# STM32H723VEH6 register map
File version: 1.0
Registers are 32-bit, access not given, reset 0x0 unless marked. A register's access mark holds for its fields unless they carry their own. Offsets are from the block's base; [hi:lo] are bit positions; {n}, {i} and the like mark numbered series.

## DMA1
Base 0x40020000
Same registers: DMA2 0x40020400
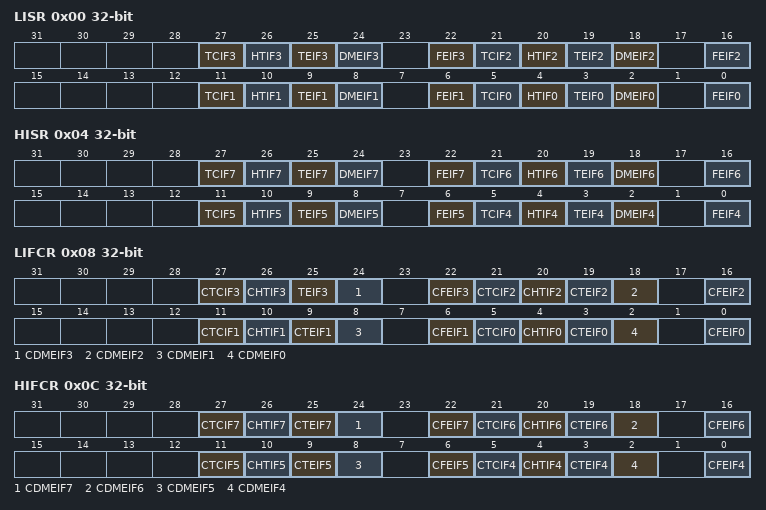
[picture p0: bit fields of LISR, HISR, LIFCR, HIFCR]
0x00 LISR
  [27] TCIF3, [26] HTIF3, [25] TEIF3, [24] DMEIF3, [22] FEIF3, [21] TCIF2, [20] HTIF2, [19] TEIF2, [18] DMEIF2, [16] FEIF2, [11] TCIF1, [10] HTIF1, [9] TEIF1, [8] DMEIF1, [6] FEIF1, [5] TCIF0, [4] HTIF0, [3] TEIF0, [2] DMEIF0, [0] FEIF0
0x04 HISR
  [27] TCIF7, [26] HTIF7, [25] TEIF7, [24] DMEIF7, [22] FEIF7, [21] TCIF6, [20] HTIF6, [19] TEIF6, [18] DMEIF6, [16] FEIF6, [11] TCIF5, [10] HTIF5, [9] TEIF5, [8] DMEIF5, [6] FEIF5, [5] TCIF4, [4] HTIF4, [3] TEIF4, [2] DMEIF4, [0] FEIF4
0x08 LIFCR
  [27] CTCIF3, [26] CHTIF3, [25] TEIF3, [24] CDMEIF3, [22] CFEIF3, [21] CTCIF2, [20] CHTIF2, [19] CTEIF2, [18] CDMEIF2, [16] CFEIF2, [11] CTCIF1, [10] CHTIF1, [9] CTEIF1, [8] CDMEIF1, [6] CFEIF1, [5] CTCIF0, [4] CHTIF0, [3] CTEIF0, [2] CDMEIF0, [0] CFEIF0
0x0C HIFCR
  [27] CTCIF7, [26] CHTIF7, [25] CTEIF7, [24] CDMEIF7, [22] CFEIF7, [21] CTCIF6, [20] CHTIF6, [19] CTEIF6, [18] CDMEIF6, [16] CFEIF6, [11] CTCIF5, [10] CHTIF5, [9] CTEIF5, [8] CDMEIF5, [6] CFEIF5, [5] CTCIF4, [4] CHTIF4, [3] CTEIF4, [2] CDMEIF4, [0] CFEIF4
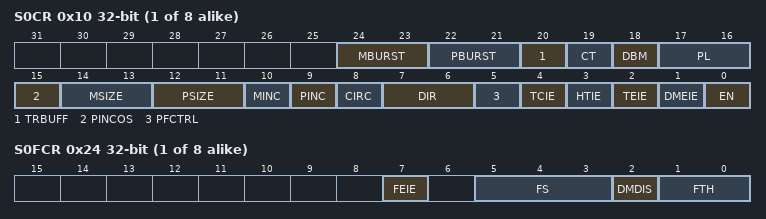
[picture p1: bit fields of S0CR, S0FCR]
{0x10+0x18*i} S{i}CR (i=0..7)
  [24:23] MBURST, [22:21] PBURST, [20] TRBUFF, [19] CT, [18] DBM, [17:16] PL, [15] PINCOS, [14:13] MSIZE, [12:11] PSIZE, [10] MINC, [9] PINC, [8] CIRC, [7:6] DIR, [5] PFCTRL, [4] TCIE, [3] HTIE, [2] TEIE, [1] DMEIE, [0] EN
{0x14+0x18*i} S{i}NDTR (i=0..7)
  [15:0] NDT
{0x18+0x18*i} S{i}PAR (i=0..7)
  [31:0] PA
{0x1C+0x18*i} S{i}M0AR (i=0..7)
  [31:0] M0A
{0x20+0x18*i} S{i}M1AR (i=0..7)
  [31:0] M1A
{0x24+0x18*i} S{i}FCR (i=0..7)
  [7] FEIE, [5:3] FS, [2] DMDIS, [1:0] FTH

## DMAMUX1
Base 0x40020800
Same registers: DMAMUX2 0x58025800
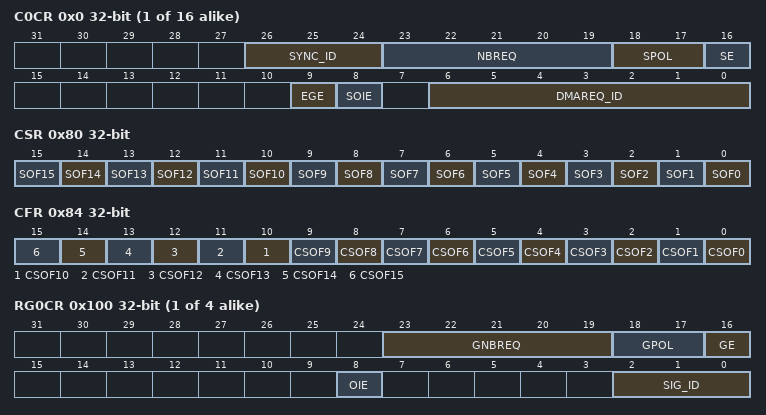
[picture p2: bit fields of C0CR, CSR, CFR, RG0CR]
{0x0+4i} C{i}CR (i=0..15)
  [26:24] SYNC_ID, [23:19] NBREQ, [18:17] SPOL, [16] SE, [9] EGE, [8] SOIE, [6:0] DMAREQ_ID
0x80 CSR
  [n] SOF{n} (n=0..15)
0x84 CFR
  [n] CSOF{n} (n=0..15)
{0x100+4i} RG{i}CR (i=0..3)
  [23:19] GNBREQ, [18:17] GPOL, [16] GE, [8] OIE, [2:0] SIG_ID
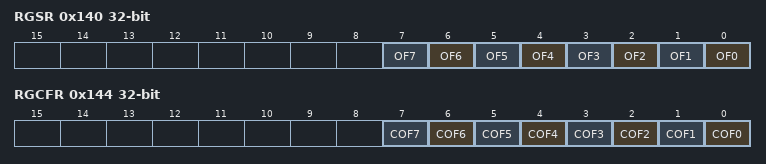
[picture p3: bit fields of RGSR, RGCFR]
0x140 RGSR
  [n] OF{n} (n=0..7)
0x144 RGCFR
  [n] COF{n} (n=0..7)

## ADC1
Base 0x40022000
Same registers: ADC2 0x40022000, ADC3 0x58026000
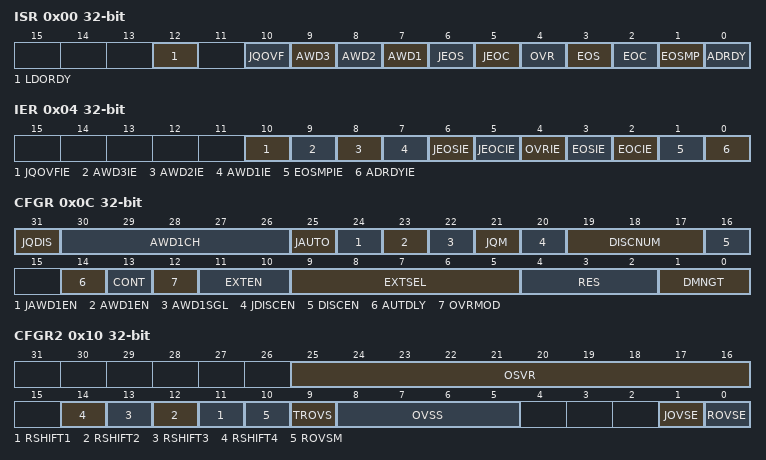
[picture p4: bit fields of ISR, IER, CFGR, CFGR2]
0x00 ISR
  [12] LDORDY, [10] JQOVF, [9] AWD3, [8] AWD2, [7] AWD1, [6] JEOS, [5] JEOC, [4] OVR, [3] EOS, [2] EOC, [1] EOSMP, [0] ADRDY
0x04 IER
  [10] JQOVFIE, [9] AWD3IE, [8] AWD2IE, [7] AWD1IE, [6] JEOSIE, [5] JEOCIE, [4] OVRIE, [3] EOSIE, [2] EOCIE, [1] EOSMPIE, [0] ADRDYIE
0x0C CFGR
  [31] JQDIS, [30:26] AWD1CH, [25] JAUTO, [24] JAWD1EN, [23] AWD1EN, [22] AWD1SGL, [21] JQM, [20] JDISCEN, [19:17] DISCNUM, [16] DISCEN, [14] AUTDLY, [13] CONT, [12] OVRMOD, [11:10] EXTEN, [9:5] EXTSEL, [4:2] RES, [1:0] DMNGT
0x10 CFGR2
  [25:16] OSVR, [n+10] RSHIFT{n} (n=1..4), [10] ROVSM, [9] TROVS, [8:5] OVSS, [1] JOVSE, [0] ROVSE
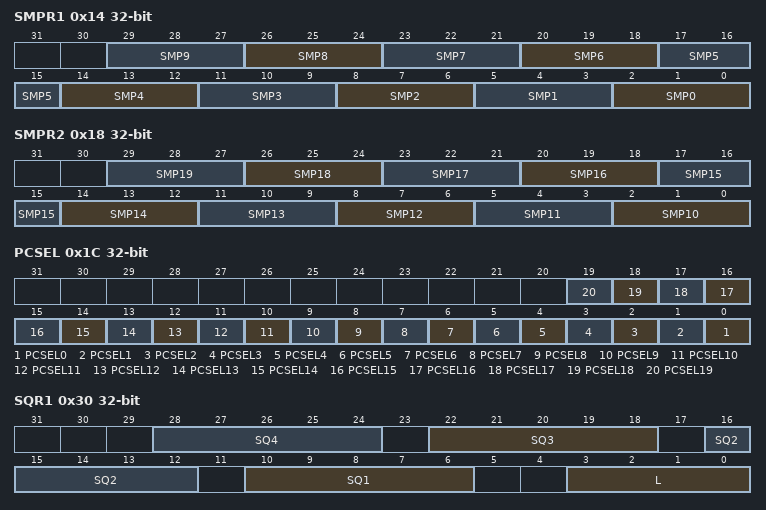
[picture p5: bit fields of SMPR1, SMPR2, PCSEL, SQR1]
0x14 SMPR1
  [3n+2:3n] SMP{n} (n=0..9)
0x18 SMPR2
  [3n-28:3n-30] SMP{n} (n=10..19)
0x1C PCSEL
  [n] PCSEL{n} (n=0..19)
0x20 LTR1
  [25:0] LTR1
0x24 HTR1
  [25:0] HTR1
0x30 SQR1
  [6n+4:6n] SQ{n} (n=1..4), [3:0] L
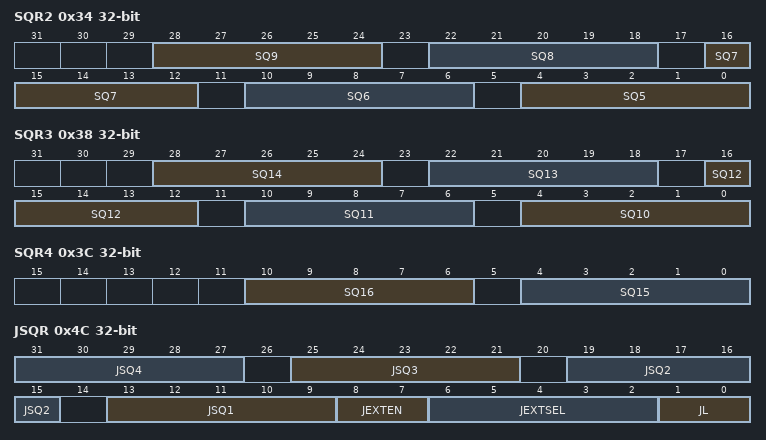
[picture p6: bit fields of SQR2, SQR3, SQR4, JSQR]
0x34 SQR2
  [6n-26:6n-30] SQ{n} (n=5..9)
0x38 SQR3
  [6n-56:6n-60] SQ{n} (n=10..14)
0x3C SQR4
  [10:6] SQ16, [4:0] SQ15
0x40 DR
  [31:0] RDATA
0x4C JSQR
  [6n+7:6n+3] JSQ{n} (n=1..4), [8:7] JEXTEN, [6:2] JEXTSEL, [1:0] JL
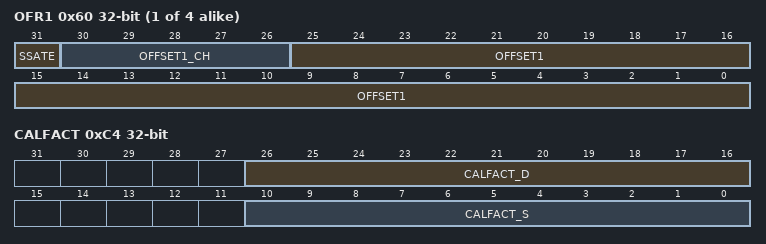
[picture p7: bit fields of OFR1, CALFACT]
{0x5C+4i} OFR{i} (i=1..4)
  [31] SSATE, [30:26] OFFSET{i}_CH, [25:0] OFFSET{i}
{0x7C+4i} JDR{i} (i=1..4)
  [31:0] JDATA{i}
0xA0 AWD2CR
  [19:0] AWD2CH
0xA4 AWD3CR
  [19:0] AWD3CH
0xB0 LTR2
  [25:0] LTR2
0xB4 HTR2
  [25:0] HTR2
0xB8 LTR3
  [25:0] LTR3
0xBC HTR3
  [25:0] HTR3
0xC0 DIFSEL
  [19:0] DIFSEL
0xC4 CALFACT
  [26:16] CALFACT_D, [10:0] CALFACT_S
0xC8 CALFACT2
  [29:0] LINCALFACT

## ETH
Base 0x40028000
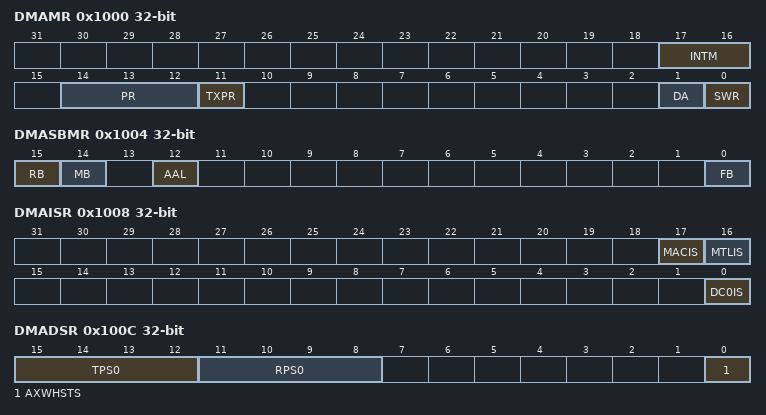
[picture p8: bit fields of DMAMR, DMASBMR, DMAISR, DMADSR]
0x1000 DMAMR
  [17:16] INTM, [14:12] PR, [11] TXPR, [1] DA, [0] SWR
0x1004 DMASBMR
  [15] RB, [14] MB, [12] AAL, [0] FB
0x1008 DMAISR
  [17] MACIS, [16] MTLIS, [0] DC0IS
0x100C DMADSR
  [15:12] TPS0, [11:8] RPS0, [0] AXWHSTS
